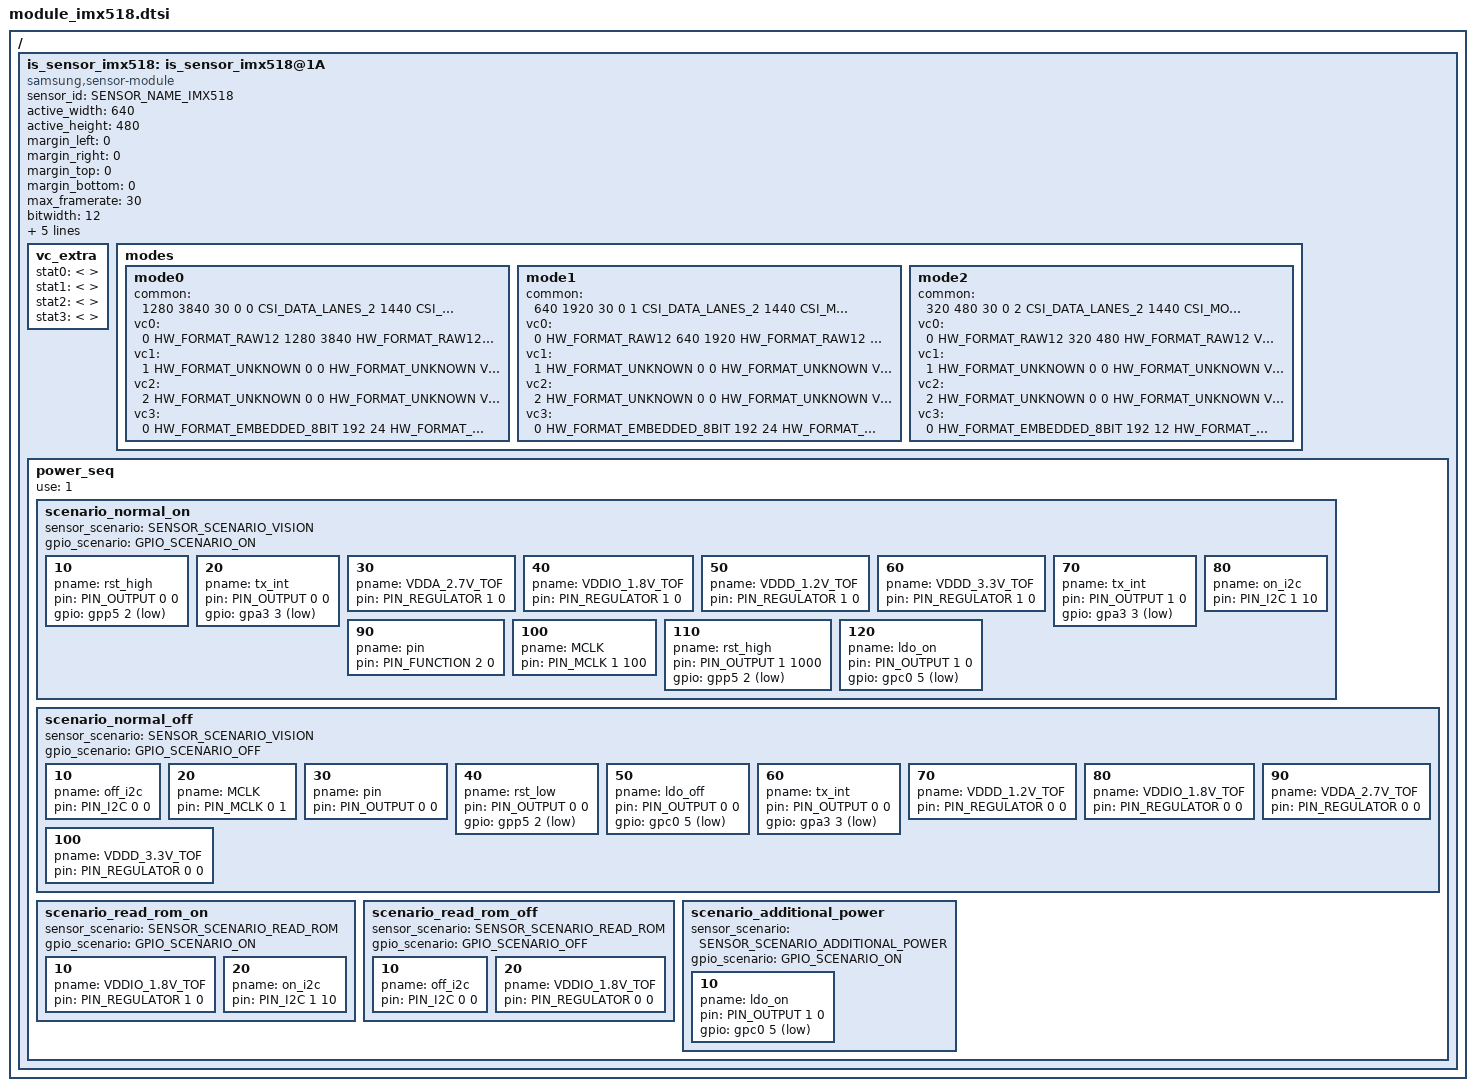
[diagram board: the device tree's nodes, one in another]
/*
 * SAMSUNG EXYNOSxxxx board camera device tree source
 *
 * Copyright (c) 2019 Samsung Electronics Co., Ltd.
 *		http://www.samsung.com
 *
 * This program is free software; you can redistribute it and/or modify
 * it under the terms of the GNU General Public License version 2 as
 * published by the Free Software Foundation.
 */

#include <dt-bindings/camera/exynos_is_dt.h>

/ {
	fragment@camera {
		target-path = "/";
		__overlay__ {
			is_sensor_imx518: is_sensor_imx518@1A {
				compatible = "samsung,sensor-module";

				/* common */
				sensor_id = <SENSOR_NAME_IMX518>;
				active_width = <640>;
				active_height = <480>;
				margin_left = <0>;
				margin_right = <0>;
				margin_top = <0>;
				margin_bottom = <0>;
				max_framerate = <30>;
				bitwidth = <12>;
				use_retention_mode = <SENSOR_RETENTION_UNSUPPORTED>;
				sensor_maker = "SONY";
				sensor_name = "IMX518";
				setfile_name = "setfile_imx518.bin";

				status = "okay";

				vc_extra {
					/* ex) statX = <stat_type, sensor_mode, max_width, max_height, max_element> */
					stat0 = </* not avaliable */>;									/* VC_BUF_DATA_TYPE_SENSOR_STAT1 */
					stat1 = </* not avaliable */>;	/* VC_BUF_DATA_TYPE_GENERAL_STAT1 */
					stat2 = </* not avaliable */>;									/* VC_BUF_DATA_TYPE_SENSOR_STAT2 */
					stat3 = </* not avaliable */>;	/* VC_BUF_DATA_TYPE_GENERAL_STAT2 */
				};

				/* sensor modes */
				modes {
						/* common = <width, height, fps, settle, mode, lane, speed, interleave, lrte, pd_mode> */
						/* vcX = <map, hwformat, width, height, hwformat, type, width, height> */
					mode0 {
						common = <1280 3840 30 0 0 CSI_DATA_LANES_2 1440 CSI_MODE_DT_ONLY LRTE_DISABLE PD_NONE>;
						vc0 = </* in */ 0 HW_FORMAT_RAW12 1280 3840	/* out */ HW_FORMAT_RAW12 VC_NOTHING 1280 3840>;
						vc1 = </* in */ 1 HW_FORMAT_UNKNOWN 0 0	/* out */ HW_FORMAT_UNKNOWN VC_NOTHING 0 0>;
						vc2 = </* in */ 2 HW_FORMAT_UNKNOWN 0 0	/* out */ HW_FORMAT_UNKNOWN VC_NOTHING 0 0>;
						vc3 = </* in */ 0 HW_FORMAT_EMBEDDED_8BIT 192 24	/* out */ HW_FORMAT_EMBEDDED_8BIT VC_NOTHING 192 24>;
					};
					mode1 {
						common = <640 1920 30 0 1 CSI_DATA_LANES_2 1440 CSI_MODE_DT_ONLY LRTE_DISABLE PD_NONE>;
						vc0 = </* in */ 0 HW_FORMAT_RAW12 640 1920	/* out */ HW_FORMAT_RAW12 VC_NOTHING 640 1920>;
						vc1 = </* in */ 1 HW_FORMAT_UNKNOWN 0 0	/* out */ HW_FORMAT_UNKNOWN VC_NOTHING 0 0>;
						vc2 = </* in */ 2 HW_FORMAT_UNKNOWN 0 0	/* out */ HW_FORMAT_UNKNOWN VC_NOTHING 0 0>;
						vc3 = </* in */ 0 HW_FORMAT_EMBEDDED_8BIT 192 24	/* out */ HW_FORMAT_EMBEDDED_8BIT VC_NOTHING 192 24>;
					};
					mode2 {
						common = <320 480 30 0 2 CSI_DATA_LANES_2 1440 CSI_MODE_DT_ONLY LRTE_DISABLE PD_NONE>;
						vc0 = </* in */ 0 HW_FORMAT_RAW12 320 480	/* out */ HW_FORMAT_RAW12 VC_NOTHING 320 480>;
						vc1 = </* in */ 1 HW_FORMAT_UNKNOWN 0 0	/* out */ HW_FORMAT_UNKNOWN VC_NOTHING 0 0>;
						vc2 = </* in */ 2 HW_FORMAT_UNKNOWN 0 0	/* out */ HW_FORMAT_UNKNOWN VC_NOTHING 0 0>;
						vc3 = </* in */ 0 HW_FORMAT_EMBEDDED_8BIT 192 12	/* out */ HW_FORMAT_EMBEDDED_8BIT VC_NOTHING 192 12>;
					};
				};

				power_seq {
					use = <1>;

					scenario_normal_on {
						sensor_scenario = <SENSOR_SCENARIO_VISION>;
						gpio_scenario = <GPIO_SCENARIO_ON>;

						/* A start node number should be over the 10 for reserved number 0~9. */
						/* pname = "name"; pin = <act value dealy voltage>; gpio = <gpx# # 0x1>; */
						10 { pname = "rst_high"; pin = <PIN_OUTPUT 0 0>; gpio = <&gpp5 2 0x1>; };
						20 { pname = "tx_int"; pin = <PIN_OUTPUT 0 0>; gpio = <&gpa3 3 0x1>; };
						30 { pname = "VDDA_2.7V_TOF"; pin = <PIN_REGULATOR 1 0>; };
						40 { pname = "VDDIO_1.8V_TOF"; pin = <PIN_REGULATOR 1 0>; };
						50 { pname = "VDDD_1.2V_TOF"; pin = <PIN_REGULATOR 1 0>; };
						60 { pname = "VDDD_3.3V_TOF"; pin = <PIN_REGULATOR 1 0>; };
						70 { pname = "tx_int"; pin = <PIN_OUTPUT 1 0>; gpio = <&gpa3 3 0x1>; };
						80 { pname = "on_i2c"; pin = <PIN_I2C 1 10>; };
						90 { pname = "pin"; pin = <PIN_FUNCTION 2 0>; };
						100 { pname = "MCLK"; pin = <PIN_MCLK 1 100>; };
						110 { pname = "rst_high"; pin = <PIN_OUTPUT 1 1000>; gpio = <&gpp5 2 0x1>; };
						120 { pname = "ldo_on"; pin = <PIN_OUTPUT 1 0>; gpio = <&gpc0 5 0x1>; };
					};

					scenario_normal_off {
						sensor_scenario = <SENSOR_SCENARIO_VISION>;
						gpio_scenario = <GPIO_SCENARIO_OFF>;

						/* A start node number should be over the 10 for reserved number 0~9. */
						/* pname = "name"; pin = <act value dealy voltage>; gpio = <gpx# # 0x1>; */
						10 { pname = "off_i2c"; pin = <PIN_I2C 0 0>; };
						20 { pname = "MCLK"; pin = <PIN_MCLK 0 1>; };
						30 { pname = "pin"; pin = <PIN_OUTPUT 0 0>; };
						40 { pname = "rst_low"; pin = <PIN_OUTPUT 0 0>; gpio = <&gpp5 2 0x1>; };
						50 { pname = "ldo_off"; pin = <PIN_OUTPUT 0 0>; gpio = <&gpc0 5 0x1>; };
						60 { pname = "tx_int"; pin = <PIN_OUTPUT 0 0>; gpio = <&gpa3 3 0x1>; };
						70 { pname = "VDDD_1.2V_TOF"; pin = <PIN_REGULATOR 0 0>; };
						80 { pname = "VDDIO_1.8V_TOF"; pin = <PIN_REGULATOR 0 0>; };
						90 { pname = "VDDA_2.7V_TOF"; pin = <PIN_REGULATOR 0 0>; };
						100 { pname = "VDDD_3.3V_TOF"; pin = <PIN_REGULATOR 0 0>; };
					};

					scenario_read_rom_on {
						sensor_scenario = <SENSOR_SCENARIO_READ_ROM>;
						gpio_scenario = <GPIO_SCENARIO_ON>;

						/* A start node number should be over the 10 for reserved number 0~9. */
						/* pname = "name"; pin = <act value dealy voltage>; gpio = <gpx# # 0x1>; */
						10 { pname = "VDDIO_1.8V_TOF"; pin = <PIN_REGULATOR 1 0>; };
						20 { pname = "on_i2c"; pin = <PIN_I2C 1 10>; };
					};

					scenario_read_rom_off {
						sensor_scenario = <SENSOR_SCENARIO_READ_ROM>;
						gpio_scenario = <GPIO_SCENARIO_OFF>;

						/* A start node number should be over the 10 for reserved number 0~9. */
						/* pname = "name"; pin = <act value dealy voltage>; gpio = <gpx# # 0x1>; */
						10 { pname = "off_i2c"; pin = <PIN_I2C 0 0>; };
						20 { pname = "VDDIO_1.8V_TOF"; pin = <PIN_REGULATOR 0 0>; };
					};

					scenario_additional_power {
						sensor_scenario = <SENSOR_SCENARIO_ADDITIONAL_POWER>;
						gpio_scenario = <GPIO_SCENARIO_ON>;

						/* A start node number should be over the 10 for reserved number 0~9. */
						/* pname = "name"; pin = <act value dealy voltage>; gpio = <gpx# # 0x1>; */
						10 { pname = "ldo_on"; pin = <PIN_OUTPUT 1 0>; gpio = <&gpc0 5 0x1>; };
					};
				};
			};
		}; /* end of __overlay__ */
	}; /* end of fragment */
}; /* end of root */
